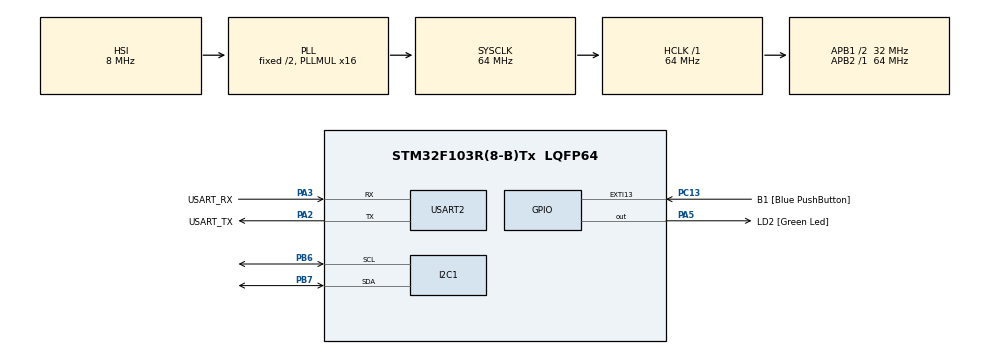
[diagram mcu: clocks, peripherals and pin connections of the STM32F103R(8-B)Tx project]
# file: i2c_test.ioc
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I2C1.I2C_Mode=I2C_Standard
Mcu.Family=STM32F1
Mcu.Name=STM32F103R(8-B)Tx
Mcu.Package=LQFP64
NVIC.EXTI15_10_IRQn=true\:0\:0\:false\:false\:true\:true\:true\:true
NVIC.PriorityGroup=NVIC_PRIORITYGROUP_4
PA13.GPIO_Label=TMS
PA13.Mode=Serial_Wire
PA13.Signal=SYS_JTMS-SWDIO
PA14.GPIO_Label=TCK
PA14.Mode=Serial_Wire
PA14.Signal=SYS_JTCK-SWCLK
PA2.GPIO_Label=USART_TX
PA2.GPIO_Mode=GPIO_MODE_AF_PP
PA2.GPIO_PuPd=GPIO_NOPULL
PA2.GPIO_Speed=GPIO_SPEED_FREQ_LOW
PA2.Mode=Asynchronous
PA2.Signal=USART2_TX
PA3.GPIO_Label=USART_RX
PA3.GPIO_Mode=GPIO_MODE_AF_PP
PA3.GPIO_PuPd=GPIO_NOPULL
PA3.GPIO_Speed=GPIO_SPEED_FREQ_LOW
PA3.Mode=Asynchronous
PA3.Signal=USART2_RX
PA5.GPIO_Label=LD2 [Green Led]
PA5.GPIO_ModeDefaultOutputPP=GPIO_MODE_OUTPUT_PP
PA5.GPIO_PuPd=GPIO_NOPULL
PA5.GPIO_Speed=GPIO_SPEED_FREQ_LOW
PA5.Signal=GPIO_Output
PB3.GPIO_Label=SWO
PB3.Signal=SYS_JTDO-TRACESWO
PB6.Mode=I2C
PB6.Signal=I2C1_SCL
PB7.Mode=I2C
PB7.Signal=I2C1_SDA
PC13-TAMPER-RTC.GPIO_Label=B1 [Blue PushButton]
PC13-TAMPER-RTC.GPIO_PuPd=GPIO_NOPULL
PC13-TAMPER-RTC.Signal=GPXTI13
PC14-OSC32_IN.Mode=LSE-External-Oscillator
PC14-OSC32_IN.Signal=RCC_OSC32_IN
PC15-OSC32_OUT.Mode=LSE-External-Oscillator
PC15-OSC32_OUT.Signal=RCC_OSC32_OUT
PD0-OSC_IN.Mode=HSE-External-Clock-Source
PD0-OSC_IN.Signal=RCC_OSC_IN
PD1-OSC_OUT.Mode=HSE-External-Clock-Source
PD1-OSC_OUT.Signal=RCC_OSC_OUT
ProjectManager.HeapSize=0x200
ProjectManager.StackSize=0x400
ProjectManager.TargetToolchain=STM32CubeIDE
RCC.AHBFreq_Value=64000000
RCC.APB1CLKDivider=RCC_HCLK_DIV2
RCC.APB1Freq_Value=32000000
RCC.APB1TimFreq_Value=64000000
RCC.APB2Freq_Value=64000000
RCC.APB2TimFreq_Value=64000000
RCC.HCLKFreq_Value=64000000
RCC.PLLMUL=RCC_PLL_MUL16
RCC.RTCClockSelection=RCC_RTCCLKSOURCE_LSE
RCC.SYSCLKFreq_VALUE=64000000
RCC.SYSCLKSource=RCC_SYSCLKSOURCE_PLLCLK
RCC.USBFreq_Value=64000000
USART2.VirtualMode=VM_ASYNC
board=NUCLEO-F103RB

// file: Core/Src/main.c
/* USER CODE BEGIN Header */
/**
  ******************************************************************************
  * @file           : main.c
  * @brief          : Main program body
  ******************************************************************************
  * @attention
  *
  * Copyright (c) 2023 STMicroelectronics.
  * All rights reserved.
  *
  * This software is licensed under terms that can be found in the LICENSE file
  * in the root directory of this software component.
  * If no LICENSE file comes with this software, it is provided AS-IS.
  *
  ******************************************************************************
  */
/* USER CODE END Header */
#include "main.h"
#include "i2c.h"
#include "usart.h"
#include "gpio.h"

/* USER CODE BEGIN Includes */
#include "lcd_i2c.h"
#include <stdbool.h>
#include <stdio.h>
/* USER CODE END Includes */

/* USER CODE BEGIN PV */
//#define EEPROM_ADDR 0xA0
//uint8_t toWrite1[] = "English is a WestGermanic language of the IndoEuropean language";
//uint8_t toWrite2[] = "The STM32 family of 32-bit microcontrollers based on Arm Cortex";
//uint8_t toWriteA[] = "Hello";
//uint8_t toWriteB[] = "Hi";
//uint8_t toWriteM[] = "Microcontroller is a compressed micro computer";
//uint8_t toWriteL[] = "EEPROM stands for electrically erasable programmable readonly M";
//uint8_t toRead1[64];
//uint8_t toRead2[64];
//uint8_t toReadA[5];
//uint8_t toReadB[2];
//uint8_t toReadM[64];
//uint8_t toReadL[64];

struct lcd_disp disp;
/* USER CODE END PV */

void SystemClock_Config(void);

int main(void)
{

  /* MCU Configuration--------------------------------------------------------*/

  /* Reset of all peripherals, Initializes the Flash interface and the Systick. */
  HAL_Init();

  /* Configure the system clock */
  SystemClock_Config();

  /* Initialize all configured peripherals */
  MX_GPIO_Init();
  MX_USART2_UART_Init();
  MX_I2C1_Init();
  /* USER CODE BEGIN 2 */
  disp.addr = (0x27 << 1);
  disp.bl = false;
  lcd_init(&disp);
  sprintf((char *)disp.f_line, "PMIK");

  lcd_display(&disp);
  //  HAL_I2C_Mem_Write(I2C_HandleTypeDef *hi2c, uint16_t DevAddress, uint16_t MemAddress,
//	//		  uint16_t MemAddSize, uint8_t *pData, uint16_t Size, uint32_t Timeout);
//	HAL_I2C_Mem_Write(&hi2c1, EEPROM_ADDR, 0, 2, toWrite1, sizeof(toWrite1), 1000);
//	HAL_I2C_Mem_Write(&hi2c1, EEPROM_ADDR, 64, 2, toWrite2, sizeof(toWrite2), 1000);
//	HAL_I2C_Mem_Write(&hi2c1, EEPROM_ADDR, 129, 2, toWriteA, sizeof(toWriteA), 1000);
//	HAL_I2C_Mem_Write(&hi2c1, EEPROM_ADDR, 189, 2, toWriteB, sizeof(toWriteB), 1000);
//	HAL_I2C_Mem_Write(&hi2c1, EEPROM_ADDR, 16000, 2, toWriteM, sizeof(toWriteM), 1000);
//	HAL_I2C_Mem_Write(&hi2c1, EEPROM_ADDR, 32704, 2, toWriteL, sizeof(toWriteL), 1000);
//
//	//  HAL_I2C_Mem_Read(I2C_HandleTypeDef *hi2c, uint16_t DevAddress, uint16_t MemAddress,
//	//		  uint16_t MemAddSize, uint8_t *pData, uint16_t Size, uint32_t Timeout);
//	HAL_I2C_Mem_Read(&hi2c1, EEPROM_ADDR, 0, 2, toRead1, sizeof(toRead1), 1000);
//	HAL_I2C_Mem_Read(&hi2c1, EEPROM_ADDR, 64, 2, toRead2, sizeof(toRead2), 1000);
//	HAL_I2C_Mem_Read(&hi2c1, EEPROM_ADDR, 129, 2, toReadA, sizeof(toReadA), 1000);
//	HAL_I2C_Mem_Read(&hi2c1, EEPROM_ADDR, 189, 2, toReadB, sizeof(toReadB), 1000);
//	HAL_I2C_Mem_Read(&hi2c1, EEPROM_ADDR, 16000, 2, toReadM, sizeof(toReadM), 1000);
//	HAL_I2C_Mem_Read(&hi2c1, EEPROM_ADDR, 32704, 2, toReadL, sizeof(toReadL), 1000);
  /* USER CODE END 2 */

  /* Infinite loop */
  while (1)
  {

  }
}

void SystemClock_Config(void)
{
  RCC_OscInitTypeDef RCC_OscInitStruct = {0};
  RCC_ClkInitTypeDef RCC_ClkInitStruct = {0};

  /** Initializes the RCC Oscillators according to the specified parameters
  * in the RCC_OscInitTypeDef structure.
  */
  RCC_OscInitStruct.OscillatorType = RCC_OSCILLATORTYPE_HSI;
  RCC_OscInitStruct.HSIState = RCC_HSI_ON;
  RCC_OscInitStruct.HSICalibrationValue = RCC_HSICALIBRATION_DEFAULT;
  RCC_OscInitStruct.PLL.PLLState = RCC_PLL_ON;
  RCC_OscInitStruct.PLL.PLLSource = RCC_PLLSOURCE_HSI_DIV2;
  RCC_OscInitStruct.PLL.PLLMUL = RCC_PLL_MUL16;
  if (HAL_RCC_OscConfig(&RCC_OscInitStruct) != HAL_OK)
  {
    Error_Handler();
  }

  /** Initializes the CPU, AHB and APB buses clocks
  */
  RCC_ClkInitStruct.ClockType = RCC_CLOCKTYPE_HCLK|RCC_CLOCKTYPE_SYSCLK
                              |RCC_CLOCKTYPE_PCLK1|RCC_CLOCKTYPE_PCLK2;
  RCC_ClkInitStruct.SYSCLKSource = RCC_SYSCLKSOURCE_PLLCLK;
  RCC_ClkInitStruct.AHBCLKDivider = RCC_SYSCLK_DIV1;
  RCC_ClkInitStruct.APB1CLKDivider = RCC_HCLK_DIV2;
  RCC_ClkInitStruct.APB2CLKDivider = RCC_HCLK_DIV1;

  if (HAL_RCC_ClockConfig(&RCC_ClkInitStruct, FLASH_LATENCY_2) != HAL_OK)
  {
    Error_Handler();
  }
}

void Error_Handler(void)
{
  __disable_irq();
  while (1)
  {
  }
}
